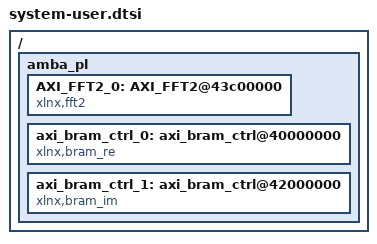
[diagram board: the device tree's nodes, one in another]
/include/ "system-conf.dtsi"
/ {
	amba_pl: amba_pl {
		AXI_FFT2_0: AXI_FFT2@43c00000 {
			compatible = "xlnx,fft2";
		};
		axi_bram_ctrl_0: axi_bram_ctrl@40000000 {
			compatible = "xlnx,bram_re";
		};
		axi_bram_ctrl_1: axi_bram_ctrl@42000000 {
			compatible = "xlnx,bram_im";
		};
	};

};
